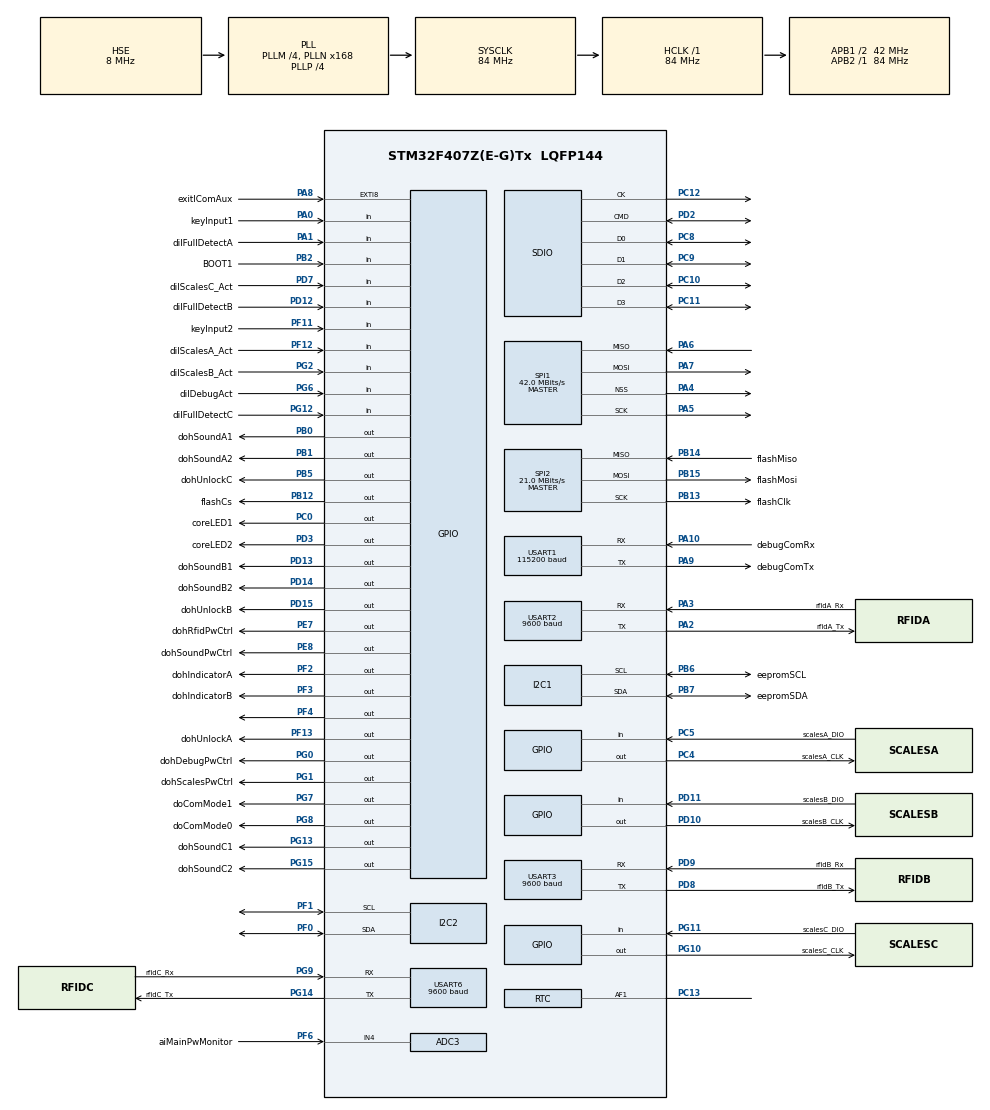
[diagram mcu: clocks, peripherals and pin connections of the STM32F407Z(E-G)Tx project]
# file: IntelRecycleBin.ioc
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ADC1.Channel-0\#ChannelRegularConversion=ADC_CHANNEL_TEMPSENSOR
ADC1.ClockPrescaler=ADC_CLOCK_SYNC_PCLK_DIV8
ADC1.ContinuousConvMode=DISABLE
ADC1.DMAContinuousRequests=DISABLE
ADC1.DataAlign=ADC_DATAALIGN_RIGHT
ADC1.DiscontinuousConvMode=DISABLE
ADC1.EOCSelection=ADC_EOC_SINGLE_CONV
ADC1.EnableAnalogWatchDog=false
ADC1.ExternalTrigConv=ADC_SOFTWARE_START
ADC1.ExternalTrigConvEdge=ADC_EXTERNALTRIGCONVEDGE_NONE
ADC1.InjNumberOfConversion=0
ADC1.NbrOfConversion=1
ADC1.NbrOfConversionFlag=1
ADC1.Rank-0\#ChannelRegularConversion=1
ADC1.Resolution=ADC_RESOLUTION_12B
ADC1.SamplingTime-0\#ChannelRegularConversion=ADC_SAMPLETIME_15CYCLES
ADC1.ScanConvMode=DISABLE
ADC1.master=1
ADC3.Channel-117\#ChannelRegularConversion=ADC_CHANNEL_4
ADC3.ClockPrescaler=ADC_CLOCK_SYNC_PCLK_DIV8
ADC3.ContinuousConvMode=DISABLE
ADC3.DMAContinuousRequests=DISABLE
ADC3.DataAlign=ADC_DATAALIGN_RIGHT
ADC3.DiscontinuousConvMode=DISABLE
ADC3.EOCSelection=ADC_EOC_SINGLE_CONV
ADC3.EnableAnalogWatchDog=false
ADC3.ExternalTrigConv=ADC_SOFTWARE_START
ADC3.ExternalTrigConvEdge=ADC_EXTERNALTRIGCONVEDGE_NONE
ADC3.InjNumberOfConversion=0
ADC3.NbrOfConversion=1
ADC3.NbrOfConversionFlag=1
ADC3.Rank-117\#ChannelRegularConversion=1
ADC3.Resolution=ADC_RESOLUTION_12B
ADC3.SamplingTime-117\#ChannelRegularConversion=ADC_SAMPLETIME_3CYCLES
ADC3.ScanConvMode=DISABLE
Dma.Request0=USART2_RX
Dma.Request1=USART3_RX
Dma.Request2=USART1_RX
Dma.Request3=USART6_RX
Dma.USART1_RX.2.Direction=DMA_PERIPH_TO_MEMORY
Dma.USART1_RX.2.FIFOMode=DMA_FIFOMODE_DISABLE
Dma.USART1_RX.2.Instance=DMA2_Stream2
Dma.USART1_RX.2.MemDataAlignment=DMA_MDATAALIGN_BYTE
Dma.USART1_RX.2.MemInc=DMA_MINC_ENABLE
Dma.USART1_RX.2.Mode=DMA_CIRCULAR
Dma.USART1_RX.2.PeriphDataAlignment=DMA_PDATAALIGN_BYTE
Dma.USART1_RX.2.PeriphInc=DMA_PINC_DISABLE
Dma.USART1_RX.2.Priority=DMA_PRIORITY_LOW
Dma.USART2_RX.0.Direction=DMA_PERIPH_TO_MEMORY
Dma.USART2_RX.0.FIFOMode=DMA_FIFOMODE_DISABLE
Dma.USART2_RX.0.Instance=DMA1_Stream5
Dma.USART2_RX.0.MemDataAlignment=DMA_MDATAALIGN_BYTE
Dma.USART2_RX.0.MemInc=DMA_MINC_ENABLE
Dma.USART2_RX.0.Mode=DMA_NORMAL
Dma.USART2_RX.0.PeriphDataAlignment=DMA_PDATAALIGN_BYTE
Dma.USART2_RX.0.PeriphInc=DMA_PINC_DISABLE
Dma.USART2_RX.0.Priority=DMA_PRIORITY_LOW
Dma.USART3_RX.1.Direction=DMA_PERIPH_TO_MEMORY
Dma.USART3_RX.1.FIFOMode=DMA_FIFOMODE_DISABLE
Dma.USART3_RX.1.Instance=DMA1_Stream1
Dma.USART3_RX.1.MemDataAlignment=DMA_MDATAALIGN_BYTE
Dma.USART3_RX.1.MemInc=DMA_MINC_ENABLE
Dma.USART3_RX.1.Mode=DMA_CIRCULAR
Dma.USART3_RX.1.PeriphDataAlignment=DMA_PDATAALIGN_BYTE
Dma.USART3_RX.1.PeriphInc=DMA_PINC_DISABLE
Dma.USART3_RX.1.Priority=DMA_PRIORITY_LOW
Dma.USART6_RX.3.Direction=DMA_PERIPH_TO_MEMORY
Dma.USART6_RX.3.FIFOMode=DMA_FIFOMODE_DISABLE
Dma.USART6_RX.3.Instance=DMA2_Stream1
Dma.USART6_RX.3.MemDataAlignment=DMA_MDATAALIGN_BYTE
Dma.USART6_RX.3.MemInc=DMA_MINC_ENABLE
Dma.USART6_RX.3.Mode=DMA_NORMAL
Dma.USART6_RX.3.PeriphDataAlignment=DMA_PDATAALIGN_BYTE
Dma.USART6_RX.3.PeriphInc=DMA_PINC_DISABLE
Dma.USART6_RX.3.Priority=DMA_PRIORITY_LOW
FREERTOS.BinarySemaphores01=comFrameRxSem,Dynamic,NULL;comFrameTxSem,Dynamic,NULL;authorizeResultSem,Dynamic,NULL;loopARxSem,Dynamic,NULL;loopBRxSem,Dynamic,NULL;loopCRxSem,Dynamic,NULL;tempADC_Sem,Dynamic,NULL;voltADC_Sem,Dynamic,NULL
FREERTOS.Mutexes01=authorizeResultMutex,Dynamic,NULL
FREERTOS.Queues01=comRxBufQ,6,comBuf_typeDef,NULL,Dynamic,NULL,NULL;userIDQueue,4,comBuf_typeDef,NULL,Dynamic,NULL,NULL;qualifiedIDQueue,4,comBuf_typeDef,NULL,Dynamic,NULL,NULL;infoIDQueue,4,comBuf_typeDef,NULL,Dynamic,NULL,NULL;comTxBufQ,5,comBuf_typeDef,NULL,Dynamic,NULL,NULL;memoryQueue,16,uint32_t,NULL,Dynamic,NULL,NULL
FREERTOS.Tasks01=defaultTask,-2,128,StartDefaultTask,Default,NULL,Dynamic,NULL,NULL;StartTask,-3,128,startTask,Default,NULL,Dynamic,NULL,NULL;LoopATask,-1,128,loopATask,As weak,NULL,Dynamic,NULL,NULL;LoopBTask,-1,128,loopBTask,As weak,NULL,Dynamic,NULL,NULL;IAP_Task,2,512,iapTask,As weak,NULL,Dynamic,NULL,NULL;ComTxTask,0,128,comTxTask,As weak,NULL,Dynamic,NULL,NULL;ComRxTask,-3,128,comRxTask,As weak,NULL,Dynamic,NULL,NULL;MemoryTask,-2,64,memoryTask,As weak,NULL,Dynamic,NULL,NULL
FREERTOS.Timers01=rfidTimer,ReadRFID,osTimerPeriodic,As external,NULL,Dynamic,NULL
FREERTOS.configCHECK_FOR_STACK_OVERFLOW=1
FREERTOS.configGENERATE_RUN_TIME_STATS=1
FREERTOS.configMINIMAL_STACK_SIZE=64
FREERTOS.configUSE_TASK_NOTIFICATIONS=0
FREERTOS.configUSE_TICKLESS_IDLE=1
FREERTOS.configUSE_TIMERS=1
Mcu.Family=STM32F4
Mcu.Name=STM32F407Z(E-G)Tx
Mcu.Package=LQFP144
NVIC.ADC_IRQn=true\:5\:0\:false\:false\:true\:true
NVIC.DMA1_Stream1_IRQn=true\:5\:0\:false\:false\:true\:true
NVIC.DMA1_Stream5_IRQn=true\:5\:0\:false\:false\:true\:true
NVIC.DMA2_Stream1_IRQn=true\:5\:0\:false\:false\:true\:true
NVIC.DMA2_Stream2_IRQn=true\:5\:0\:false\:false\:true\:true
NVIC.PriorityGroup=NVIC_PRIORITYGROUP_4
NVIC.SPI2_IRQn=true\:5\:0\:false\:false\:true\:true
NVIC.USART1_IRQn=true\:5\:0\:false\:false\:true\:true
NVIC.USART2_IRQn=true\:5\:0\:false\:false\:true\:true
NVIC.USART3_IRQn=true\:5\:0\:false\:false\:true\:true
NVIC.USART6_IRQn=true\:5\:0\:false\:false\:true\:true
PA0-WKUP.GPIO_Label=keyInput1
PA0-WKUP.Signal=GPIO_Input
PA1.GPIO_Label=dilFullDetectA
PA1.Signal=GPIO_Input
PA10.GPIO_Label=debugComRx
PA10.Mode=Asynchronous
PA10.Signal=USART1_RX
PA11.Signal=USB_OTG_FS_DM
PA12.Signal=USB_OTG_FS_DP
PA13.Mode=JTAG_5_pins
PA13.Signal=SYS_JTMS-SWDIO
PA14.Mode=JTAG_5_pins
PA14.Signal=SYS_JTCK-SWCLK
PA15.Mode=JTAG_5_pins
PA15.Signal=SYS_JTDI
PA2.GPIO_Label=rfidA_Tx
PA2.Mode=Asynchronous
PA2.Signal=USART2_TX
PA3.GPIO_Label=rfidA_Rx
PA3.Mode=Asynchronous
PA3.Signal=USART2_RX
PA4.Mode=NSS_Signal_Hard_Output
PA4.Signal=SPI1_NSS
PA5.Mode=Full_Duplex_Master
PA5.Signal=SPI1_SCK
PA6.Mode=Full_Duplex_Master
PA6.Signal=SPI1_MISO
PA7.Mode=Full_Duplex_Master
PA7.Signal=SPI1_MOSI
PA8.GPIO_Label=exitlComAux
PA8.GPIO_PuPd=GPIO_PULLUP
PA8.Signal=GPXTI8
PA9.GPIO_Label=debugComTx
PA9.Mode=Asynchronous
PA9.Signal=USART1_TX
PB0.GPIO_Label=dohSoundA1
PB0.Signal=GPIO_Output
PB1.GPIO_Label=dohSoundA2
PB1.Signal=GPIO_Output
PB12.GPIO_Label=flashCs
PB12.Signal=GPIO_Output
PB13.GPIO_Label=flashClk
PB13.Mode=Full_Duplex_Master
PB13.Signal=SPI2_SCK
PB14.GPIO_Label=flashMiso
PB14.Mode=Full_Duplex_Master
PB14.Signal=SPI2_MISO
PB15.GPIO_Label=flashMosi
PB15.Mode=Full_Duplex_Master
PB15.Signal=SPI2_MOSI
PB2.GPIO_Label=BOOT1
PB2.Signal=GPIO_Input
PB3.Mode=JTAG_5_pins
PB3.Signal=SYS_JTDO-SWO
PB4.Mode=JTAG_5_pins
PB4.Signal=SYS_JTRST
PB5.GPIO_Label=dohUnlockC
PB5.Signal=GPIO_Output
PB6.GPIO_Label=eepromSCL
PB6.Mode=I2C
PB6.Signal=I2C1_SCL
PB7.GPIO_Label=eepromSDA
PB7.Mode=I2C
PB7.Signal=I2C1_SDA
PB8.Signal=DCMI_D6
PB9.Signal=DCMI_D7
PC0.GPIO_Label=coreLED1
PC0.Signal=GPIO_Output
PC10.Mode=SD_4_bits_Wide_bus
PC10.Signal=SDIO_D2
PC11.Mode=SD_4_bits_Wide_bus
PC11.Signal=SDIO_D3
PC12.Mode=SD_4_bits_Wide_bus
PC12.Signal=SDIO_CK
PC13-ANTI_TAMP.Mode=Calibration_512Hz
PC13-ANTI_TAMP.Signal=RTC_AF1
PC14-OSC32_IN.Mode=LSE-External-Oscillator
PC14-OSC32_IN.Signal=RCC_OSC32_IN
PC15-OSC32_OUT.Mode=LSE-External-Oscillator
PC15-OSC32_OUT.Signal=RCC_OSC32_OUT
PC4.GPIO_Label=scalesA_CLK
PC4.Signal=GPIO_Output
PC5.GPIO_Label=scalesA_DIO
PC5.GPIO_PuPd=GPIO_PULLUP
PC5.Signal=GPIO_Input
PC6.Signal=DCMI_D0
PC7.Signal=DCMI_D1
PC8.Mode=SD_4_bits_Wide_bus
PC8.Signal=SDIO_D0
PC9.Mode=SD_4_bits_Wide_bus
PC9.Signal=SDIO_D1
PD10.GPIO_Label=scalesB_CLK
PD10.Signal=GPIO_Output
PD11.GPIO_Label=scalesB_DIO
PD11.GPIO_PuPd=GPIO_PULLUP
PD11.Signal=GPIO_Input
PD12.GPIO_Label=dilFullDetectB
PD12.Signal=GPIO_Input
PD13.GPIO_Label=dohSoundB1
PD13.Signal=GPIO_Output
PD14.GPIO_Label=dohSoundB2
PD14.Signal=GPIO_Output
PD15.GPIO_Label=dohUnlockB
PD15.Signal=GPIO_Output
PD2.Mode=SD_4_bits_Wide_bus
PD2.Signal=SDIO_CMD
PD3.GPIO_Label=coreLED2
PD3.Signal=GPIO_Output
PD7.GPIO_Label=dilScalesC_Act
PD7.GPIO_PuPd=GPIO_PULLUP
PD7.Signal=GPIO_Input
PD8.GPIO_Label=rfidB_Tx
PD8.Mode=Asynchronous
PD8.Signal=USART3_TX
PD9.GPIO_Label=rfidB_Rx
PD9.Mode=Asynchronous
PD9.Signal=USART3_RX
PE0.Signal=DCMI_D2
PE1.Signal=DCMI_D3
PE4.Signal=DCMI_D4
PE7.GPIO_Label=dohRfidPwCtrl
PE7.Signal=GPIO_Output
PE8.GPIO_Label=dohSoundPwCtrl
PE8.Signal=GPIO_Output
PF0.Mode=I2C
PF0.Signal=I2C2_SDA
PF1.Mode=I2C
PF1.Signal=I2C2_SCL
PF11.GPIO_Label=keyInput2
PF11.Signal=GPIO_Input
PF12.GPIO_Label=dilScalesA_Act
PF12.GPIO_PuPd=GPIO_PULLUP
PF12.Signal=GPIO_Input
PF13.GPIO_Label=dohUnlockA
PF13.Signal=GPIO_Output
PF2.GPIO_Label=dohIndicatorA
PF2.Signal=GPIO_Output
PF3.GPIO_Label=dohIndicatorB
PF3.Signal=GPIO_Output
PF4.Signal=GPIO_Output
PF6.GPIO_Label=aiMainPwMonitor
PF6.Mode=IN4
PF6.Signal=ADC3_IN4
PF7.Signal=ADC3_IN5
PF8.Signal=ADC3_IN6
PG0.GPIO_Label=dohDebugPwCtrl
PG0.Signal=GPIO_Output
PG1.GPIO_Label=dohScalesPwCtrl
PG1.Signal=GPIO_Output
PG10.GPIO_Label=scalesC_CLK
PG10.Signal=GPIO_Output
PG11.GPIO_Label=scalesC_DIO
PG11.GPIO_PuPd=GPIO_PULLUP
PG11.Signal=GPIO_Input
PG12.GPIO_Label=dilFullDetectC
PG12.GPIO_PuPd=GPIO_PULLUP
PG12.Signal=GPIO_Input
PG13.GPIO_Label=dohSoundC1
PG13.Signal=GPIO_Output
PG14.GPIO_Label=rfidC_Tx
PG14.Mode=Asynchronous
PG14.Signal=USART6_TX
PG15.GPIO_Label=dohSoundC2
PG15.Signal=GPIO_Output
PG2.GPIO_Label=dilScalesB_Act
PG2.GPIO_PuPd=GPIO_PULLUP
PG2.Signal=GPIO_Input
PG6.GPIO_Label=dilDebugAct
PG6.Signal=GPIO_Input
PG7.GPIO_Label=doComMode1
PG7.Signal=GPIO_Output
PG8.GPIO_Label=doComMode0
PG8.Signal=GPIO_Output
PG9.GPIO_Label=rfidC_Rx
PG9.Mode=Asynchronous
PG9.Signal=USART6_RX
PH0-OSC_IN.Mode=HSE-External-Oscillator
PH0-OSC_IN.Signal=RCC_OSC_IN
PH1-OSC_OUT.Mode=HSE-External-Oscillator
PH1-OSC_OUT.Signal=RCC_OSC_OUT
ProjectManager.HeapSize=0x200
ProjectManager.StackSize=0x500
ProjectManager.TargetToolchain=TrueSTUDIO
RCC.48MHZClocksFreq_Value=48000000
RCC.AHBFreq_Value=84000000
RCC.APB1CLKDivider=RCC_HCLK_DIV2
RCC.APB1Freq_Value=42000000
RCC.APB1TimFreq_Value=84000000
RCC.APB2Freq_Value=84000000
RCC.APB2TimFreq_Value=84000000
RCC.CortexFreq_Value=84000000
RCC.HCLKFreq_Value=84000000
RCC.HSE_VALUE=8000000
RCC.HSI_VALUE=16000000
RCC.PLLM=4
RCC.PLLN=168
RCC.PLLP=RCC_PLLP_DIV4
RCC.PLLQ=7
RCC.PLLSourceVirtual=RCC_PLLSOURCE_HSE
RCC.RCC_RTC_Clock_Source=RCC_RTCCLKSOURCE_LSI
RCC.RCC_RTC_Clock_SourceVirtual=RCC_RTCCLKSOURCE_LSE
RCC.SYSCLKFreq_VALUE=84000000
RCC.SYSCLKSource=RCC_SYSCLKSOURCE_PLLCLK
RCC.VCOOutputFreq_Value=336000000
SPI1.BaudRatePrescaler=SPI_BAUDRATEPRESCALER_2
SPI1.CalculateBaudRate=42.0 MBits/s
SPI1.Direction=SPI_DIRECTION_2LINES
SPI1.Mode=SPI_MODE_MASTER
SPI1.VirtualNSS=VM_NSSHARD
SPI1.VirtualType=VM_MASTER
SPI2.BaudRatePrescaler=SPI_BAUDRATEPRESCALER_2
SPI2.CalculateBaudRate=21.0 MBits/s
SPI2.Direction=SPI_DIRECTION_2LINES
SPI2.Mode=SPI_MODE_MASTER
SPI2.VirtualType=VM_MASTER
USART1.BaudRate=115200
USART1.VirtualMode=VM_ASYNC
USART2.BaudRate=9600
USART2.VirtualMode=VM_ASYNC
USART3.BaudRate=9600
USART3.VirtualMode=VM_ASYNC
USART6.BaudRate=9600
USART6.VirtualMode=VM_ASYNC
VP_ADC1_TempSens_Input.Mode=IN-TempSens
VP_ADC1_Vbat_Input.Mode=IN-Vbat
VP_CRC_VS_CRC.Mode=CRC_Activate
VP_FREERTOS_VS_ENABLE.Mode=Enabled
VP_RNG_VS_RNG.Mode=RNG_Activate
VP_RTC_VS_RTC_Activate.Mode=RTC_Enabled
board=IntelRecycleBin

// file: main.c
/**
  ******************************************************************************
  * File Name          : main.c
  * Description        : Main program body
  ******************************************************************************
  *
  * Copyright (c) 2017 STMicroelectronics International N.V.
  * All rights reserved.
  *
  * Redistribution and use in source and binary forms, with or without
  * modification, are permitted, provided that the following conditions are met:
  *
  * 1. Redistribution of source code must retain the above copyright notice,
  *    this list of conditions and the following disclaimer.
  * 2. Redistributions in binary form must reproduce the above copyright notice,
  *    this list of conditions and the following disclaimer in the documentation
  *    and/or other materials provided with the distribution.
  * 3. Neither the name of STMicroelectronics nor the names of other
  *    contributors to this software may be used to endorse or promote products
  *    derived from this software without specific written permission.
  * 4. This software, including modifications and/or derivative works of this
  *    software, must execute solely and exclusively on microcontroller or
  *    microprocessor devices manufactured by or for STMicroelectronics.
  * 5. Redistribution and use of this software other than as permitted under
  *    this license is void and will automatically terminate your rights under
  *    this license.
  *
  * THIS SOFTWARE IS PROVIDED BY STMICROELECTRONICS AND CONTRIBUTORS "AS IS"
  * AND ANY EXPRESS, IMPLIED OR STATUTORY WARRANTIES, INCLUDING, BUT NOT
  * LIMITED TO, THE IMPLIED WARRANTIES OF MERCHANTABILITY, FITNESS FOR A
  * PARTICULAR PURPOSE AND NON-INFRINGEMENT OF THIRD PARTY INTELLECTUAL PROPERTY
  * RIGHTS ARE DISCLAIMED TO THE FULLEST EXTENT PERMITTED BY LAW. IN NO EVENT
  * SHALL STMICROELECTRONICS OR CONTRIBUTORS BE LIABLE FOR ANY DIRECT, INDIRECT,
  * INCIDENTAL, SPECIAL, EXEMPLARY, OR CONSEQUENTIAL DAMAGES (INCLUDING, BUT NOT
  * LIMITED TO, PROCUREMENT OF SUBSTITUTE GOODS OR SERVICES; LOSS OF USE, DATA,
  * OR PROFITS; OR BUSINESS INTERRUPTION) HOWEVER CAUSED AND ON ANY THEORY OF
  * LIABILITY, WHETHER IN CONTRACT, STRICT LIABILITY, OR TORT (INCLUDING
  * NEGLIGENCE OR OTHERWISE) ARISING IN ANY WAY OUT OF THE USE OF THIS SOFTWARE,
  * EVEN IF ADVISED OF THE POSSIBILITY OF SUCH DAMAGE.
  *
  ******************************************************************************
  */
#include "main.h"
#include "stm32f4xx_hal.h"
#include "cmsis_os.h"
#include "adc.h"
#include "crc.h"
#include "dma.h"
#include "i2c.h"
#include "rng.h"
#include "rtc.h"
#include "sdio.h"
#include "spi.h"
#include "usart.h"
#include "gpio.h"

/* USER CODE BEGIN PV */
/* Private variables ---------------------------------------------------------*/

/* USER CODE END PV */

void SystemClock_Config(void);
void Error_Handler(void);
void MX_FREERTOS_Init(void);

/* USER CODE BEGIN PFP */
/* Private function prototypes -----------------------------------------------*/

/* USER CODE END PFP */

int main(void)
{

  /* MCU Configuration----------------------------------------------------------*/

  /* Reset of all peripherals, Initializes the Flash interface and the Systick. */
  HAL_Init();

  /* Configure the system clock */
  SystemClock_Config();

  /* Initialize all configured peripherals */
  MX_GPIO_Init();
  MX_DMA_Init();
  MX_I2C2_Init();
  MX_RNG_Init();
  MX_RTC_Init();
  MX_SDIO_SD_Init();
  MX_SPI2_Init();
  MX_USART6_UART_Init();
  MX_ADC1_Init();
  MX_USART1_UART_Init();
  MX_USART2_UART_Init();
  MX_USART3_UART_Init();
  MX_I2C1_Init();
  MX_ADC3_Init();
  MX_SPI1_Init();
  MX_CRC_Init();

  /* Call init function for freertos objects (in freertos.c) */
  MX_FREERTOS_Init();

  /* Start scheduler */
  osKernelStart();

  /* We should never get here as control is now taken by the scheduler */

  /* Infinite loop */
  while (1)
  {

  }

}

/** System Clock Configuration
*/
void SystemClock_Config(void)
{

  RCC_OscInitTypeDef RCC_OscInitStruct;
  RCC_ClkInitTypeDef RCC_ClkInitStruct;
  RCC_PeriphCLKInitTypeDef PeriphClkInitStruct;

    /**Configure the main internal regulator output voltage
    */
  __HAL_RCC_PWR_CLK_ENABLE();

  __HAL_PWR_VOLTAGESCALING_CONFIG(PWR_REGULATOR_VOLTAGE_SCALE1);

    /**Initializes the CPU, AHB and APB busses clocks
    */
  RCC_OscInitStruct.OscillatorType = RCC_OSCILLATORTYPE_LSI|RCC_OSCILLATORTYPE_HSE;
  RCC_OscInitStruct.HSEState = RCC_HSE_ON;
  RCC_OscInitStruct.LSIState = RCC_LSI_ON;
  RCC_OscInitStruct.PLL.PLLState = RCC_PLL_ON;
  RCC_OscInitStruct.PLL.PLLSource = RCC_PLLSOURCE_HSE;
  RCC_OscInitStruct.PLL.PLLM = 4;
  RCC_OscInitStruct.PLL.PLLN = 168;
  RCC_OscInitStruct.PLL.PLLP = RCC_PLLP_DIV4;
  RCC_OscInitStruct.PLL.PLLQ = 7;
  if (HAL_RCC_OscConfig(&RCC_OscInitStruct) != HAL_OK)
  {
    Error_Handler();
  }

    /**Initializes the CPU, AHB and APB busses clocks
    */
  RCC_ClkInitStruct.ClockType = RCC_CLOCKTYPE_HCLK|RCC_CLOCKTYPE_SYSCLK
                              |RCC_CLOCKTYPE_PCLK1|RCC_CLOCKTYPE_PCLK2;
  RCC_ClkInitStruct.SYSCLKSource = RCC_SYSCLKSOURCE_PLLCLK;
  RCC_ClkInitStruct.AHBCLKDivider = RCC_SYSCLK_DIV1;
  RCC_ClkInitStruct.APB1CLKDivider = RCC_HCLK_DIV2;
  RCC_ClkInitStruct.APB2CLKDivider = RCC_HCLK_DIV1;

  if (HAL_RCC_ClockConfig(&RCC_ClkInitStruct, FLASH_LATENCY_2) != HAL_OK)
  {
    Error_Handler();
  }

  PeriphClkInitStruct.PeriphClockSelection = RCC_PERIPHCLK_RTC;
  PeriphClkInitStruct.RTCClockSelection = RCC_RTCCLKSOURCE_LSI;
  if (HAL_RCCEx_PeriphCLKConfig(&PeriphClkInitStruct) != HAL_OK)
  {
    Error_Handler();
  }

    /**Configure the Systick interrupt time
    */
  HAL_SYSTICK_Config(HAL_RCC_GetHCLKFreq()/1000);

    /**Configure the Systick
    */
  HAL_SYSTICK_CLKSourceConfig(SYSTICK_CLKSOURCE_HCLK);

  /* SysTick_IRQn interrupt configuration */
  HAL_NVIC_SetPriority(SysTick_IRQn, 15, 0);
}

void Error_Handler(void)
{
  while(1)
  {
  }
}

/************************ (C) COPYRIGHT STMicroelectronics *****END OF FILE****/

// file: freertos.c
/**
  ******************************************************************************
  * File Name          : freertos.c
  * Description        : Code for freertos applications
  ******************************************************************************
  *
  * Copyright (c) 2017 STMicroelectronics International N.V.
  * All rights reserved.
  *
  * Redistribution and use in source and binary forms, with or without
  * modification, are permitted, provided that the following conditions are met:
  *
  * 1. Redistribution of source code must retain the above copyright notice,
  *    this list of conditions and the following disclaimer.
  * 2. Redistributions in binary form must reproduce the above copyright notice,
  *    this list of conditions and the following disclaimer in the documentation
  *    and/or other materials provided with the distribution.
  * 3. Neither the name of STMicroelectronics nor the names of other
  *    contributors to this software may be used to endorse or promote products
  *    derived from this software without specific written permission.
  * 4. This software, including modifications and/or derivative works of this
  *    software, must execute solely and exclusively on microcontroller or
  *    microprocessor devices manufactured by or for STMicroelectronics.
  * 5. Redistribution and use of this software other than as permitted under
  *    this license is void and will automatically terminate your rights under
  *    this license.
  *
  * THIS SOFTWARE IS PROVIDED BY STMICROELECTRONICS AND CONTRIBUTORS "AS IS"
  * AND ANY EXPRESS, IMPLIED OR STATUTORY WARRANTIES, INCLUDING, BUT NOT
  * LIMITED TO, THE IMPLIED WARRANTIES OF MERCHANTABILITY, FITNESS FOR A
  * PARTICULAR PURPOSE AND NON-INFRINGEMENT OF THIRD PARTY INTELLECTUAL PROPERTY
  * RIGHTS ARE DISCLAIMED TO THE FULLEST EXTENT PERMITTED BY LAW. IN NO EVENT
  * SHALL STMICROELECTRONICS OR CONTRIBUTORS BE LIABLE FOR ANY DIRECT, INDIRECT,
  * INCIDENTAL, SPECIAL, EXEMPLARY, OR CONSEQUENTIAL DAMAGES (INCLUDING, BUT NOT
  * LIMITED TO, PROCUREMENT OF SUBSTITUTE GOODS OR SERVICES; LOSS OF USE, DATA,
  * OR PROFITS; OR BUSINESS INTERRUPTION) HOWEVER CAUSED AND ON ANY THEORY OF
  * LIABILITY, WHETHER IN CONTRACT, STRICT LIABILITY, OR TORT (INCLUDING
  * NEGLIGENCE OR OTHERWISE) ARISING IN ANY WAY OUT OF THE USE OF THIS SOFTWARE,
  * EVEN IF ADVISED OF THE POSSIBILITY OF SUCH DAMAGE.
  *
  ******************************************************************************
  */

#include "FreeRTOS.h"
#include "task.h"
#include "cmsis_os.h"

osThreadId defaultTaskHandle;
osThreadId StartTaskHandle;
osThreadId LoopATaskHandle;
osThreadId LoopBTaskHandle;
osThreadId IAP_TaskHandle;
osThreadId ComTxTaskHandle;
osThreadId ComRxTaskHandle;
osThreadId MemoryTaskHandle;
osMessageQId comRxBufQHandle;
osMessageQId userIDQueueHandle;
osMessageQId qualifiedIDQueueHandle;
osMessageQId infoIDQueueHandle;
osMessageQId comTxBufQHandle;
osMessageQId memoryQueueHandle;
osTimerId rfidTimerHandle;
osMutexId authorizeResultMutexHandle;
osSemaphoreId comFrameRxSemHandle;
osSemaphoreId comFrameTxSemHandle;
osSemaphoreId authorizeResultSemHandle;
osSemaphoreId loopARxSemHandle;
osSemaphoreId loopBRxSemHandle;
osSemaphoreId loopCRxSemHandle;
osSemaphoreId tempADC_SemHandle;
osSemaphoreId voltADC_SemHandle;

void StartDefaultTask(void const * argument);
void startTask(void const * argument);
void loopATask(void const * argument);
void loopBTask(void const * argument);
void iapTask(void const * argument);
void comTxTask(void const * argument);
void comRxTask(void const * argument);
void memoryTask(void const * argument);
extern void ReadRFID(void const * argument);

void MX_FREERTOS_Init(void); /* (MISRA C 2004 rule 8.1) */

/* Pre/Post sleep processing prototypes */
void PreSleepProcessing(uint32_t *ulExpectedIdleTime);
void PostSleepProcessing(uint32_t *ulExpectedIdleTime);

/* Hook prototypes */
void configureTimerForRunTimeStats(void);
unsigned long getRunTimeCounterValue(void);
void vApplicationStackOverflowHook(xTaskHandle xTask, signed char *pcTaskName);

/* USER CODE BEGIN 1 */
/* Functions needed when configGENERATE_RUN_TIME_STATS is on */
__weak void configureTimerForRunTimeStats(void)
{

}

__weak unsigned long getRunTimeCounterValue(void)
{
return 0;
}
/* USER CODE END 1 */

/* USER CODE BEGIN 4 */
__weak void vApplicationStackOverflowHook(xTaskHandle xTask, signed char *pcTaskName)
{
   /* Run time stack overflow checking is performed if
   configCHECK_FOR_STACK_OVERFLOW is defined to 1 or 2. This hook function is
   called if a stack overflow is detected. */
}
/* USER CODE END 4 */

/* USER CODE BEGIN PREPOSTSLEEP */
__weak void PreSleepProcessing(uint32_t *ulExpectedIdleTime)
{
/* place for user code */
}

__weak void PostSleepProcessing(uint32_t *ulExpectedIdleTime)
{
/* place for user code */
}
/* USER CODE END PREPOSTSLEEP */

/* Init FreeRTOS */

void MX_FREERTOS_Init(void) {

  /* Create the mutex(es) */
  /* definition and creation of authorizeResultMutex */
  osMutexDef(authorizeResultMutex);
  authorizeResultMutexHandle = osMutexCreate(osMutex(authorizeResultMutex));

  /* Create the semaphores(s) */
  /* definition and creation of comFrameRxSem */
  osSemaphoreDef(comFrameRxSem);
  comFrameRxSemHandle = osSemaphoreCreate(osSemaphore(comFrameRxSem), 1);

  /* definition and creation of comFrameTxSem */
  osSemaphoreDef(comFrameTxSem);
  comFrameTxSemHandle = osSemaphoreCreate(osSemaphore(comFrameTxSem), 1);

  /* definition and creation of authorizeResultSem */
  osSemaphoreDef(authorizeResultSem);
  authorizeResultSemHandle = osSemaphoreCreate(osSemaphore(authorizeResultSem), 1);

  /* definition and creation of loopARxSem */
  osSemaphoreDef(loopARxSem);
  loopARxSemHandle = osSemaphoreCreate(osSemaphore(loopARxSem), 1);

  /* definition and creation of loopBRxSem */
  osSemaphoreDef(loopBRxSem);
  loopBRxSemHandle = osSemaphoreCreate(osSemaphore(loopBRxSem), 1);

  /* definition and creation of loopCRxSem */
  osSemaphoreDef(loopCRxSem);
  loopCRxSemHandle = osSemaphoreCreate(osSemaphore(loopCRxSem), 1);

  /* definition and creation of tempADC_Sem */
  osSemaphoreDef(tempADC_Sem);
  tempADC_SemHandle = osSemaphoreCreate(osSemaphore(tempADC_Sem), 1);

  /* definition and creation of voltADC_Sem */
  osSemaphoreDef(voltADC_Sem);
  voltADC_SemHandle = osSemaphoreCreate(osSemaphore(voltADC_Sem), 1);

  /* Create the timer(s) */
  /* definition and creation of rfidTimer */
  osTimerDef(rfidTimer, ReadRFID);
  rfidTimerHandle = osTimerCreate(osTimer(rfidTimer), osTimerPeriodic, NULL);

  /* Create the thread(s) */
  /* definition and creation of defaultTask */
  osThreadDef(defaultTask, StartDefaultTask, osPriorityLow, 0, 128);
  defaultTaskHandle = osThreadCreate(osThread(defaultTask), NULL);

  /* definition and creation of StartTask */
  osThreadDef(StartTask, startTask, osPriorityIdle, 0, 128);
  StartTaskHandle = osThreadCreate(osThread(StartTask), NULL);

  /* definition and creation of LoopATask */
  osThreadDef(LoopATask, loopATask, osPriorityBelowNormal, 0, 128);
  LoopATaskHandle = osThreadCreate(osThread(LoopATask), NULL);

  /* definition and creation of LoopBTask */
  osThreadDef(LoopBTask, loopBTask, osPriorityBelowNormal, 0, 128);
  LoopBTaskHandle = osThreadCreate(osThread(LoopBTask), NULL);

  /* definition and creation of IAP_Task */
  osThreadDef(IAP_Task, iapTask, osPriorityHigh, 0, 512);
  IAP_TaskHandle = osThreadCreate(osThread(IAP_Task), NULL);

  /* definition and creation of ComTxTask */
  osThreadDef(ComTxTask, comTxTask, osPriorityNormal, 0, 128);
  ComTxTaskHandle = osThreadCreate(osThread(ComTxTask), NULL);

  /* definition and creation of ComRxTask */
  osThreadDef(ComRxTask, comRxTask, osPriorityIdle, 0, 128);
  ComRxTaskHandle = osThreadCreate(osThread(ComRxTask), NULL);

  /* definition and creation of MemoryTask */
  osThreadDef(MemoryTask, memoryTask, osPriorityLow, 0, 64);
  MemoryTaskHandle = osThreadCreate(osThread(MemoryTask), NULL);

  /* Create the queue(s) */
  /* definition and creation of comRxBufQ */
  osMessageQDef(comRxBufQ, 6, comBuf_typeDef);
  comRxBufQHandle = osMessageCreate(osMessageQ(comRxBufQ), NULL);

  /* definition and creation of userIDQueue */
  osMessageQDef(userIDQueue, 4, comBuf_typeDef);
  userIDQueueHandle = osMessageCreate(osMessageQ(userIDQueue), NULL);

  /* definition and creation of qualifiedIDQueue */
  osMessageQDef(qualifiedIDQueue, 4, comBuf_typeDef);
  qualifiedIDQueueHandle = osMessageCreate(osMessageQ(qualifiedIDQueue), NULL);

  /* definition and creation of infoIDQueue */
  osMessageQDef(infoIDQueue, 4, comBuf_typeDef);
  infoIDQueueHandle = osMessageCreate(osMessageQ(infoIDQueue), NULL);

  /* definition and creation of comTxBufQ */
  osMessageQDef(comTxBufQ, 5, comBuf_typeDef);
  comTxBufQHandle = osMessageCreate(osMessageQ(comTxBufQ), NULL);

  /* definition and creation of memoryQueue */
  osMessageQDef(memoryQueue, 16, uint32_t);
  memoryQueueHandle = osMessageCreate(osMessageQ(memoryQueue), NULL);

}

/* StartDefaultTask function */
void StartDefaultTask(void const * argument)
{

  for(;;)
  {
    osDelay(1);
  }
}

/* startTask function */
void startTask(void const * argument)
{
  for(;;)
  {
    osDelay(1);
  }
}

/* loopATask function */
__weak void loopATask(void const * argument)
{
  for(;;)
  {
    osDelay(1);
  }
}

/* loopBTask function */
__weak void loopBTask(void const * argument)
{
  for(;;)
  {
    osDelay(1);
  }
}

/* iapTask function */
__weak void iapTask(void const * argument)
{
  for(;;)
  {
    osDelay(1);
  }
}

/* comTxTask function */
__weak void comTxTask(void const * argument)
{
  for(;;)
  {
    osDelay(1);
  }
}

/* comRxTask function */
__weak void comRxTask(void const * argument)
{
  for(;;)
  {
    osDelay(1);
  }
}

/* memoryTask function */
__weak void memoryTask(void const * argument)
{
  for(;;)
  {
    osDelay(1);
  }
}

/************************ (C) COPYRIGHT STMicroelectronics *****END OF FILE****/
